# myir register map
Vendor: overlord; File version: 0.0.0
CPU: CA53 r0p0, little endian, no MPU, FPU, I-cache, D-cache, 0 interrupt priority bits
Registers are 32-bit, read-write, reset 0x0 unless marked. A register's access mark holds for its fields unless they carry their own. Offsets are from the block's base; lines under a group give offsets from that group; [hi:lo] are bit positions; {n}, {i} and the like mark numbered series; 'fields as' and 'values as' point back to an identical list; <NAME> marks a mode.

## Memory map
0xFF0F0000 QSPI size 0x828 — Quad SPI Controller
0xFF160000 SD0 size 0xFE — SDIO 0 Controller
0xFF170000 SD1 size 0xFE — SDIO 0 Controller

## Further device data
cpus:
  a53.0 endian=little
  a53.1 endian=little
  a53.2 endian=little
  a53.3 endian=little
  r5f.0 endian=little
  r5f.1 endian=little
  pmu endian=little

## QSPI — Quad SPI Controller
Base 0xFF0F0000
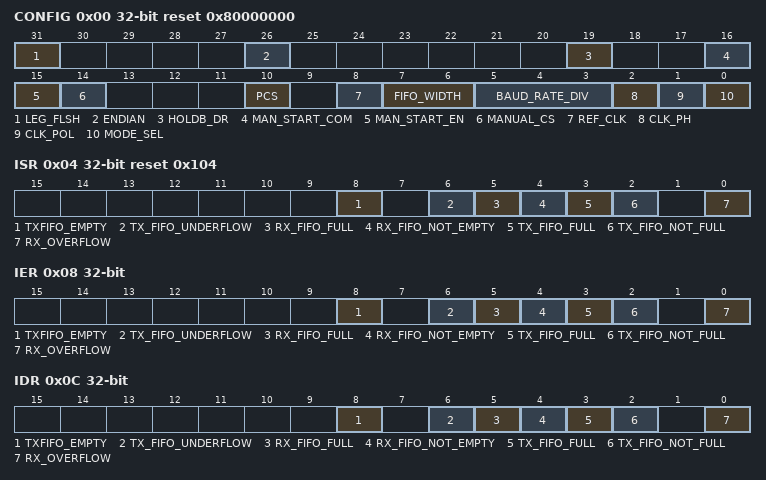
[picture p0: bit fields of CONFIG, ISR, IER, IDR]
0x00 CONFIG reset 0x80000000 — QSPI configuration register
  [31] LEG_FLSH — If this mode is disabled, the core will operate in standard SPI mode, with no dual- or quad-bit input or output capability; the extended bits will be configured as inputs to prevent any driver contention on these pins. If enabled, flash memory interface instructions are automatically recognized and the I/O configured accordingly.
  [26] ENDIAN — 1: big endian format when writing to the transmit data register 0x1C or reading from the receive data register 0x20.
  [19] HOLDB_DR — If not set, then external pull up is required on HOLDb and WPn pins. Note that this bit doesn't affect the quad (4-bit) mode as Controller always drives these pins in quad mode. It is highly recommended to set this bit always(irrespective of mode of operation) while using QSPI.
  [16] MAN_START_COM
  [15] MAN_START_EN
  [14] MANUAL_CS
  [10] PCS — In manual CS mode, this bit should be programmed before writing Transmit Data Registers (TXDx).
  [8] REF_CLK — Must be 0
  [7:6] FIFO_WIDTH — All other settings are not supported.
  [5:3] BAUD_RATE_DIV — This is the only baud rate setting that can be used if the loopback clock is enabled [USE_LPBK]. 001: divide by 4 010: divide by 8 011: divide by 16 100: divide by 32 101: divide by 64 110: divide by 128 111: divide by 256
  [2] CLK_PH
  [1] CLK_POL
  [0] MODE_SEL — In other boot modes, this bit must be set before using QSPI.
0x04 ISR reset 0x104 — Interrupt Status
  [8] TXFIFO_EMPTY — 1: TX FIFO is empty.
  [6] TX_FIFO_UNDERFLOW — 1: underflow is detected. Write 1 to this bit location to clear
  [5] RX_FIFO_FULL — 1: FIFO is full.
  [4] RX_FIFO_NOT_EMPTY — 1: FIFO has more than or equal to RX THRESHOLD entries.
  [3] TX_FIFO_FULL
  [2] TX_FIFO_NOT_FULL — 1: FIFO has less than TX THRESHOLD entries.
  [0] RX_OVERFLOW — 1: overflow occurred. Write 1 to this bit location to clear.
0x08 IER — Interrupt Enable
  [8] TXFIFO_EMPTY, [6] TX_FIFO_UNDERFLOW, [5] RX_FIFO_FULL, [4] RX_FIFO_NOT_EMPTY, [3] TX_FIFO_FULL, [2] TX_FIFO_NOT_FULL, [0] RX_OVERFLOW
0x0C IDR — Interrupt Disable
  fields as IER
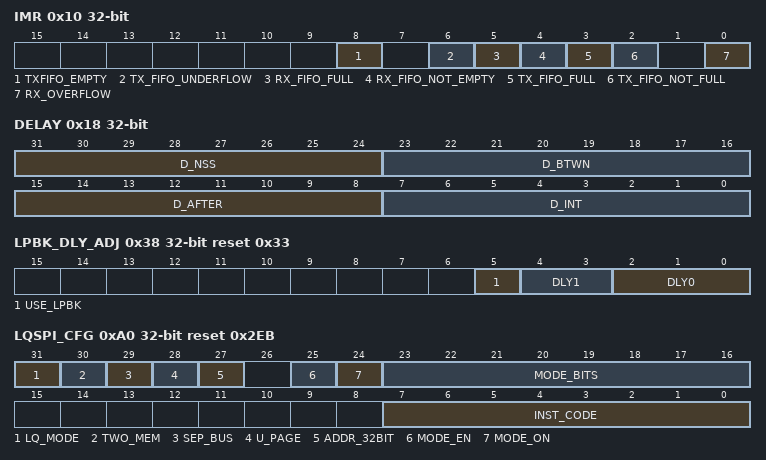
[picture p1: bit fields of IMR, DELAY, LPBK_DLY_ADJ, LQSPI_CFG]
0x10 IMR — Interrupt Un-Mask (enabled)
  fields as IER
0x14 LQSPI_EN — LQSPI Enable
  [0] SPI_EN — 1: enable the SPI. Note: Change this value only when controller is not communicating with the memory device.
0x18 DELAY — Timing Control Delay
  [31:24] D_NSS, [23:16] D_BTWN, [15:8] D_AFTER, [7:0] D_INT
0x1C TXD0 — Transmit Data, 4 Bytes
  [31:0] TXD
0x20 RX_DATA — Receive Data in RX FIFO
  [31:0] RX_FIFO_DATA
0x24 SLAVE_IDLE_COUNT reset 0xFF
0x28 TX_THRES reset 0x1 — TX FIFO Threshold
  [31:0] THRESHOLD_OF_TX_FIFO
0x2C RX_THRES reset 0x1 — RX FIFO Threshold
  [31:0] THRESHOLD_OF_RX_FIFO
0x30 GPIO reset 0x1 — Write Protection Output
  [0] WP_N — 0: output low. 1: output high (reset default). The active low function may be inverted externally for devices requiring an active high write protect signal. Note: Change this value only when controller is not communicating with the memory device.
0x38 LPBK_DLY_ADJ reset 0x33 — Loopback Master Clock Delay Adjustment
  [5] USE_LPBK — Note: Change this value only when controller is not communicating with the memory device.
  [4:3] DLY1 — Note: Change this value only when controller is not communicating with the memory device.
  [2:0] DLY0 — Note: Change this value only when controller is not communicating with the memory device.
0x80 TXD1 — Transmit Data, 1 Byte
  [31:0] TXD — In little endian mode (default), only bits 7:0 are valid, bits 31:8 are ignored. In big endian mode, only the 8 MSB bits are valid.
0x84 TXD2 — Transmit Data, 2 Byte
  [31:0] TXD — In little endian mode (default), only bits 15:0 are valid, bits 31:16 are ignored. In big endian mode, only the 16 MSB bits are valid.
0x88 TXD3 — Transmit Data, 3 Bytes
  [31:0] TXD — In little endian mode (default), only bits 23:0 are valid, bits 31:24 are ignored. In big endian mode, only the 24 MSB bits are valid.
0xA0 LQSPI_CFG reset 0x2EB — Configuration
  [31] LQ_MODE — 1: Legacy LQSPI, Linear Quad-SPI. Note: Change this value only when controller is not communicating with the memory device.
  [30] TWO_MEM — 1: Two memory devices. Note: Change this value only when controller is not communicating with the memory device.
  [29] SEP_BUS — 1: Separate memory intefaces. This bit only has meaning if [TWO_MEM] = 1. Note: Change this value only when controller is not communicating with the memory device.
  [28] U_PAGE — 1: Upper memory page. This bit only has meaning if: [TWO_MEM] = 1 (two devices) [SEP_BUS] = 0 (one interface) IO mode is not supported in LQSPI; [U_PAGE] selects the lower or upper memory for configuration or read/write operations. Note: Change this value only when controller is not communicating with the memory device.
  [27] ADDR_32BIT — 1: Five zero bits & lower 27 bits of AXI address. Note: Change this value only when controller is not communicating with the memory device.
  [25] MODE_EN — 1: Send MODE_BITS[23:16]. Must be set = 1 for dual or quad I/O read (specified through [7:0]). Must be clear = 0 for all other read modes as they do not have mode bits. If this bit is 0, [MODE_ON, 24] and [MODE_BITS] are ignored. Relationship of bits [25], [24] and [23:16] are related: if ( [ Bit25 == 0 ] && [ Bit24 == x ] ) then [ Bits23:16 = x ] if ( [ Bit25 == 1 ] && [ Bit24 == 0 ] ) then [ Bits23:16 = ~(8'bxx10xxxx) ] if ( [ Bit25 == 1 ] && [ Bit24 == 1 ] ) then [ Bits23:16 = 8'bxx10xxxx ]. Note: Change this value only when controller is not communicating with the memory device.
  [24] MODE_ON — 0: Instruction code is sent for all read transfers. 1: Instruction code is sent only for first read transfer. This bit applies when [MODE_EN, 25] is set = 1. This bit is configured in association with [MODE_BITS]. For Winbond devices, this bit must be set = 1 if the [MODE_BITS] = 8'bxx10xxxx, else clear = 0. Note: Change this value only when the controller is not communicating with the memory device.
  [23:16] MODE_BITS — These bits apply when [MODE_EN, 25] = 1. Required for both dual I/O read and quad I/O read. See Flash memory vendor's datasheet for more information on the mode bits. For the Winbond device, the continuous read mode value is 8'bxx10xxxx to skip the instruction code for the next read transfer, else instruction code is sent for all read transfers. Bit 24 has to be configured accordingly with this value. Note: Change this value only when controller is not communicating with the memory device.
  [7:0] INST_CODE — The known read instruction codes are: 8'h03 - Read 8'h0B - Fast read 8'h3B - Fast read dual output 8'h6B - Fast read quad output 8'hBB - Fast read dual I/O 8'hEB - Fast read quad I/O 8'h13 - Four Byte Address Read 8'h0C - Four Byte Address Fast read 8'h3C - Four Byte Address Fast read dual output 8'h6C - Four Byte Address Fast read quad output 8'hBC - Four Byte Address Fast read dual I/O 8'hEC - Four Byte Address Fast read quad I/O This is a static signal - should not be changed while controller is actively transmitting/receiving data to/from Flash device
0xA4 LQSPI_STS 9-bit — Status
  [2] D_FSM_ERR, [1] WR_RECVD
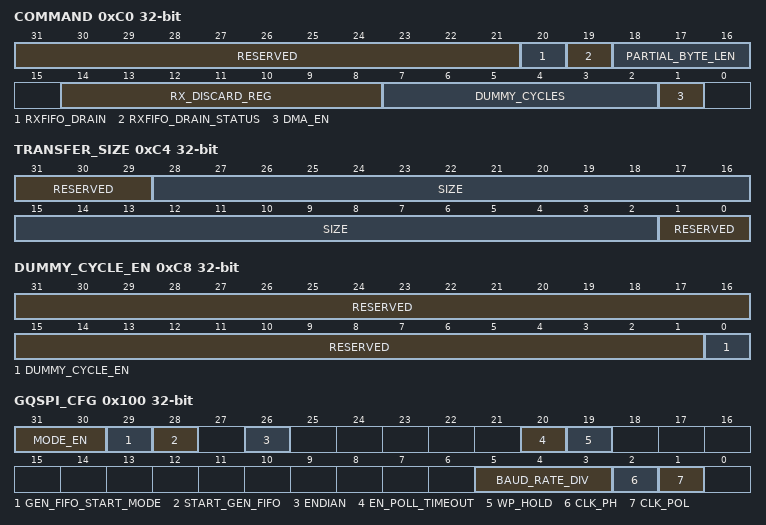
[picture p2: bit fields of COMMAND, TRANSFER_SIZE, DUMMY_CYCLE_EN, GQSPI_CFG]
0xC0 COMMAND — Command control
  [31:21] RESERVED — Return 0 when read. Writes ignored.
  [20] RXFIFO_DRAIN — This bit can be set for any write transfer to the Flash so that the HW will discard the data captured while transmitting the write data. 0: Do not discard the data in RXFIFO. 1: Discard the data in RXFIFO. Note: Change this value only when controller is not communicating with the memory device.
  [19] RXFIFO_DRAIN_STATUS — 0: RXFIFO_DRAIN is reset. 1: RXFIFO_DRAIN is set.
  [18:16] PARTIAL_BYTE_LEN — (TXDx length - PARTIAL_BYTE_LEN) is the number of bits to be transmitted For example, if only 4 bits to be transmitted, program PARTIAL_BYTE_LEN with a value of 4 and then configure TXD1 register. Similar way to transmit 12 bits, program PARTIAL_BYTE_LEN a value of 4 and then configure TXD2 register. Value in this files is cleared by HW soon after completing transmission of partial byte. SW need to write into this register again if need to transfer partial byte. This is a static signal - should not be changed while controller is actively transmitting/receiving data to/from Flash device
  [14:8] RX_DISCARD_REG — In general value in this field should be equal to QSPI clocks required to transmit Command+Address+Dummy cycles. This is a static signal - should not be changed while controller is actively transmitting/receiving data to/from Flash device
  [7:2] DUMMY_CYCLES — This is a static signal - should not be changed while controller is actively transmitting/receiving data to/from Flash device
  [1] DMA_EN — And the encoding is as mentioned below {DMA_EN, LQSPI_CFG[31]}: 01: Linear Mode. 10: DMA Mode. Others: reserved. Never set both the [DMA_EN] and LQSPI_SFG [31] bits to 1 as it is not a valid condition. This is a static signal - should not be changed while controller is actively transmitting/receiving data to/from Flash device
0xC4 TRANSFER_SIZE
  [31:29] RESERVED — Return 0 when read. Writes ignored.
  [28:2] SIZE — (2 lsb's are 0) The value in this register signifies the number of words to be read from memory. This is a static signal - should not be changed while controller is actively transmitting/receiving data to/from Flash device
  [1:0] RESERVED — Return 0 when read. Writes ignored.
0xC8 DUMMY_CYCLE_EN — Dummy Cycles Enable
  [31:1] RESERVED — Return 0 when read. Writes ignored.
  [0] DUMMY_CYCLE_EN — This bit is applicable only in Linear mode. This bit should not be used in DMA mode. 0: Disable using dummy cycle value. 1: Enable using dummy cycle value. This is a static signal - should not be changed while controller is actively transmitting/receiving data to/from Flash device
0xFC MOD_ID reset 0x1090101 — Module Identification
0x100 GQSPI_CFG — GQSPI Configuration
  [31:30] MODE_EN
  [29] GEN_FIFO_START_MODE — 1: Manual Start Mode. Note: Change this value only when controller is not communicating with the memory device.
  [28] START_GEN_FIFO — 0:disable executing requests. 1: enable executing requests. Note: Change this value only when controller is not communicating with the memory device.
  [26] ENDIAN — 1: big endian. Note: Change this value only when controller is not communicating with the memory device.
  [20] EN_POLL_TIMEOUT — 1: enable. Note: Change this value only when controller is not communicating with the memory device.
  [19] WP_HOLD — If not set, then external pull up is required on HOLDb and WPn pins. Note that this bit doesn't affect the quad(4-bit) mode as Controller always drives these pins in quad mode. It is highly recommended to set this bit always(irrespective of mode of operation) while using GQSPI Note: Change this value only when controller is not communicating with the memory device.
  [5:3] BAUD_RATE_DIV — 001: divide by 4. 010: divide by 8. 011: divide by 16. 100: divide by 32. 101: divide by 64. 110: divide by 128. 111: divide by 256. Note: 000 is requried for loopback, [USE_LPBK]. Note: Change this value only when controller is not communicating with the memory device.
  [2] CLK_PH — Note: Change this value only when controller is not communicating with the memory device.
  [1] CLK_POL — 0: QSPI clock is quiescent low. 1: QSPI clock is quiescent high. Note: For [CLK_PH, CLK_POL], only 2'b11 and 2'b00 are supported. Note: Change this value only when controller is not communicating with the memory device.
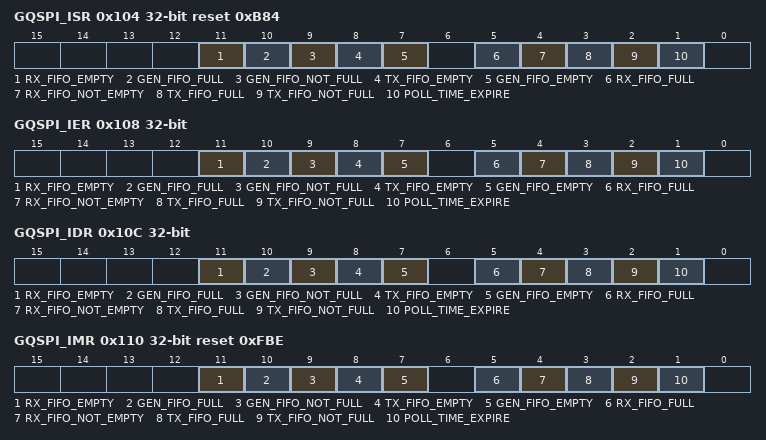
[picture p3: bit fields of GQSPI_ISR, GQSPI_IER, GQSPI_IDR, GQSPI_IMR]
0x104 GQSPI_ISR reset 0xB84 — Generic QSPI interrupt status
  [11] RX_FIFO_EMPTY, [10] GEN_FIFO_FULL, [9] GEN_FIFO_NOT_FULL, [8] TX_FIFO_EMPTY, [7] GEN_FIFO_EMPTY, [5] RX_FIFO_FULL, [4] RX_FIFO_NOT_EMPTY, [3] TX_FIFO_FULL, [2] TX_FIFO_NOT_FULL, [1] POLL_TIME_EXPIRE
0x108 GQSPI_IER — GQSPI Interrupt Enable
  fields as GQSPI_ISR
0x10C GQSPI_IDR — GQSPI Interrupt disable
  fields as GQSPI_ISR
0x110 GQSPI_IMR reset 0xFBE — GQSPI Interrupt Mask
  fields as GQSPI_ISR
0x114 GQSPI_EN — GQSPI_Enable
  [0] GQSPI_EN
0x11C GQSPI_TXD — GQSPI Transmit Data
  [31:0] TX_DATA
0x120 GQSPI_RXD — GQSPI Receive Data
  [31:0] RX_DATA
0x128 GQSPI_TX_THRESH reset 0x1 — GQSPI TX FIFO Threshold Level
  [5:0] LEVEL_TX_FIFO — Note: Change this value only when controller is not communicating with the memory device.
0x12C GQSPI_RX_THRESH reset 0x1 — GQSPI RX FIFO Threshold Level
  [5:0] LEVEL_RX_FIFO
0x130 GQSPI_GPIO reset 0x1 — GQSPI GPIO for Write Protect
  [0] WP_N — Write Protect output for flash devices supporting this function. Active low (may be inverted externally to the core if required for flash devices requiring active high write protect signal.) Note: Change this value only when controller is not communicating with the memory device.
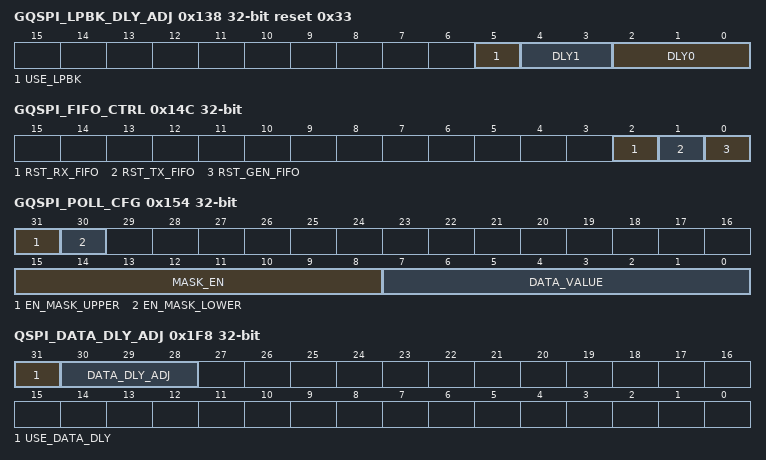
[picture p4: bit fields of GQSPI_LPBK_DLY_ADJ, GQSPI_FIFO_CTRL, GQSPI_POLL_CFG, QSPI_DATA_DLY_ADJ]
0x138 GQSPI_LPBK_DLY_ADJ reset 0x33 — GQSPI Loopback clock delay adjustment Register
  fields as LPBK_DLY_ADJ
0x140 GQSPI_GEN_FIFO — GQSPI Generic FIFO Configuration
  [19:0] GEN_DATA
0x144 GQSPI_SEL — GQSPI Select
  [0] GENERIC_QSPI_SEL — Note: Change this value only when controller is not communicating with the memory device.
0x14C GQSPI_FIFO_CTRL — GQSPI FIFO Control
  [2] RST_RX_FIFO — This bit should be used only when GQSPI is in IO mode (GQSPI_CFG.MODE_EN=0x0). Switch to IO mode if operating in DMA Mode. After RST_RX_FIFO bit is written, Controller takes few clock cycles to update the RX_FIFO_Empty status bit. Software can read the RX_FIFO_empty bit twice to allow enough time for the controller to update the status bit.
  [1] RST_TX_FIFO — After RST_TX_FIFO bit is written, Controller takes few clock cycles to update the TX_FIFO_Empty status bit. Software can read the TX_FIFO_empty bit twice to allow enough time for the controller to update the status bit.
  [0] RST_GEN_FIFO — After RST_GEN_FIFO bit is written, Controller takes few clock cycles to update the Gen_FIFO_Empty status bit. Software can read the Gen_FIFO_empty bit twice to allow enough time for the controller to update the status bit.
0x150 GQSPI_GF_THRESH reset 0x10 — GQSPI Generic FIFO Threshold Level
  [4:0] LEVEL_GF_FIFO — Note: Change this value only when controller is not communicating with the memory device.
0x154 GQSPI_POLL_CFG — GQSPI Poll Configuration Register
  [31] EN_MASK_UPPER — 1: Enable. Note: Change this value only when controller is not polling.
  [30] EN_MASK_LOWER — 1: Enable. This is a static signal - should not be changed while polling operation is in progress.
  [15:8] MASK_EN — When all the bits are zero, no masking is used and all the 8 bits of POLL_DATA field will be used for comparison during Poll. Note: Change this value only when controller is not polling.
  [7:0] DATA_VALUE — When Poll bit of Generic FIFO is set, Generic QSPI Controller continuously reads the data and checks with the POLL_DATA value. When the received data matches with the POLL_DATA filed, Generic QSPI Controller continues executing the next entry in the Generic FIFO. If the value is not matched and EN_POLL_TIMEOUT is set, poll operation will be terminated after POLL_TIMEOUT clock cycles. This is a static signal - should not be changed while polling operation is in progress.
0x158 GQSPI_P_TIMEOUT — GQSPI Poll Time out
  [31:0] VALUE — Interrupt will be provided to indicate that the timer is expired. Note: Change this value only when controller is not polling.
0x1F8 QSPI_DATA_DLY_ADJ — QSPI RX Data Delay
  [31] USE_DATA_DLY, [30:28] DATA_DLY_ADJ
0x1FC GQSPI_MOD_ID reset 0x10A0000 — GQSPI Module Identification register
  [31:0] MOD_ID
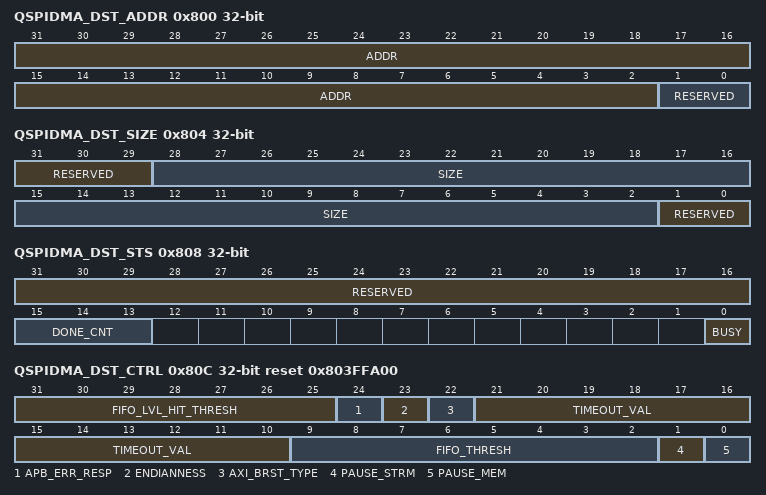
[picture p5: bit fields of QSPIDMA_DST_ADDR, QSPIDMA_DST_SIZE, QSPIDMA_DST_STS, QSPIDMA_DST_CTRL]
0x800 QSPIDMA_DST_ADDR — DMA destination memory address
  [31:2] ADDR — (2 lsb's are 0) This field must be written initially before a DMA operation is started. In this case, it indicates the memory destination address the DMA will begin writing to. Note: Change this value only when controller is not communicating with the memory device.
  [1:0] RESERVED — Return 0 when read. Writes ignored.
0x804 QSPIDMA_DST_SIZE — DMA transfer payload
  [31:29] RESERVED — Return 0 when read. Writes ignored.
  [28:2] SIZE — (2 lsb's are 0) The action of writing to this register starts a DMA transfer of length SIZE, moving data from the stream interface to ADDR. In this case, it indicates the total payload that the DMA will move from stream to memory. Note: Change this value only when controller is not communicating with the memory device.
  [1:0] RESERVED — Return 0 when read. Writes ignored.
0x808 QSPIDMA_DST_STS — General DST DMA Status
  [31:16] RESERVED — Return 0 when read. Writes ignored.
  [15:13] DONE_CNT — A finished transfer is acknowledged by clearing the interrupt status flag 'DONE". This count is cleared by an explicit write of 3'b111 to this field.
  [0] BUSY — BUSY=0: implies DMA is DONE with the transfer, the DST FIFO and any associated pipeline registers are empty. DMA may accept a new command. Note that, BUSY essentially indicates that the DMA still has remaining work to do. BUSY will reflect this status irrespective of whether the PAUSE_* is asserted or not.
0x80C QSPIDMA_DST_CTRL reset 0x803FFA00 — General DST DMA Control
  [31:25] FIFO_LVL_HIT_THRESH — 7'h00: Reserved etc 7'h0F: Reserved 7'h10: Threshold is 17 entries etc 7'h7A: Threshold is 123 entries 7'h7B: Reserved etc 7'h7F: Reserved Note that "7'h10" is the minimum and "7'h7A" is the max value that should be programmed This is a static signal - should not be changed while block is actively processing commands
  [24] APB_ERR_RESP
  [23] ENDIANNESS
  [22] AXI_BRST_TYPE
  [21:10] TIMEOUT_VAL — There are 2 physical timers, qualified with TIMEOUT_EN, that will compare against this value: 1. Timeout counter starts to run when data is provided to the AXI write channel (memory) interface and backpressure is observed. As soon as backpressure is removed, the timer is reset. When timer expires, it stops running. 2. Timeout counter runs whenever the DMA is active. Whenever a data beat is provided by the SSS, the timer is reset. When timer expires, it stops running. TIMEOUT_VAL field is interpreted as follows: Final timeout value = TIMEOUT_VAL * timeout_prescale_period where "timeout_prescale_period" is the period of the enable that is generated by the TIMEOUT_PRE. Examples (prescaler set to maximum of 4096 clk (~2.5ns) cycles) 12'h000: Final Timeout after 1 * (4096 * 2.5ns)] => 10.244 us 12'h001: Final Timeout after 2 * (4096 * 2.5ns)] => 20.48 us etc 12'hFFF: Final Timeout after 4096 * (4096 * 2.5ns)] => 41.94 ms Note that if PAUSE_MEM is asserted, timeout counter #1 will be paused and if PAUSE_STRM is asserted, timeout counter #2 will be paused. When either of the 2 timers expire, this register requires an explicit write of 12'hFFF to clear them - both will be cleared. Note: Change this value only when controller is not processing commands.
  [9:2] FIFO_THRESH — This is the FIFO threshold used to trigger the FIFO_THRESHOLD_HIT interrupt. 8'h00: Threshold is 0 entries 8'h01: Threshold is 1 entry etc 8'h80: Threshold is 128 entries Note that the interrupt will be triggered when the FIFO hits this threshold, irrespective of whether it is on the way up or down. Note: Change this value only when controller is not processing commands.
  [1] PAUSE_STRM — This in effect will lead to the emptying of the DST FIFO. 0: DMA operates as usual. If previously PAUSED, it will continue on where it left off. Note. H/W has no means to apply backpressure to the stream interface. If PAUSE_STRM is asserted, the DMA will drop the stream data. This makes PAUSE mode functionally equivalent to as if the fifo were full. The value of PAUSE_STRM may therefore be limited to debug/verification only.
  [0] PAUSE_MEM — This in effect will eventually lead to the filling of the DST FIFO. Write memory commands that are already outstanding will continue to be processed, but no new write commands will be issued to memory while PAUSE_MEM is asserted. 0: DMA operates as usual. If previously PAUSED, it will continue on where it left off.
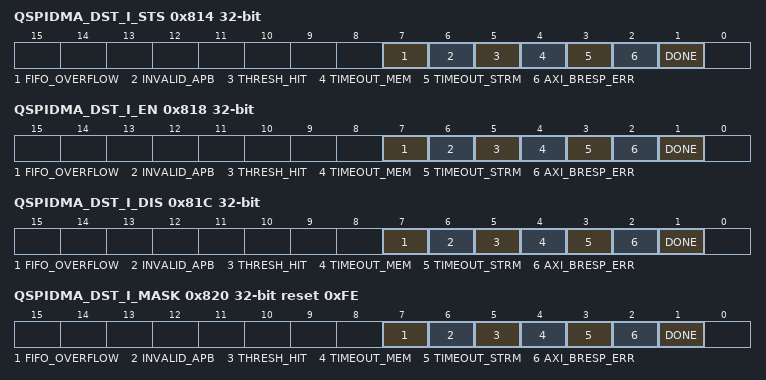
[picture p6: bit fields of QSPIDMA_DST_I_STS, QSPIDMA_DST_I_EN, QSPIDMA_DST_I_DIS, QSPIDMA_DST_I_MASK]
0x814 QSPIDMA_DST_I_STS — DST DMA Interrupt Status
  [7] FIFO_OVERFLOW — No backpressure mechanism exists on the stream interface in this direction. If the FIFO is full and 1 more data beat is produced by the stream interface, this bit will be set and the data beat will be discarded. If [PAUSE_STRM] is asserted and the stream interface produces a beat of data, the beat will be discarded and [FIFO_OVERFLOW] will be set.
  [6] INVALID_APB — The access request did not reach a register.
  [5] THRESH_HIT — The watermark value is set via the [FIFO_THRESH] bitfield.
  [4] TIMEOUT_MEM — DST DMA sees backpressure on AXI write data interface. Refer to [TIMEOUT_VAL] description for exact timeout duration and conditions.
  [3] TIMEOUT_STRM — DST DMA sees delay on SSS DST interface. Refer to [TIMEOUT_VAL] description for exact timeout duration and conditions.
  [2] AXI_BRESP_ERR — BRESP=DECERR/SLVERR.
  [1] DONE — The last associated AXI memory write command has been issued and processed (SIZE=0), all data has been sent (DST FIFO is empty) and all outstanding BRESP's have been received.
0x818 QSPIDMA_DST_I_EN — DST DMA Interrupt Enable
  [7] FIFO_OVERFLOW, [6] INVALID_APB, [5] THRESH_HIT, [4] TIMEOUT_MEM, [3] TIMEOUT_STRM, [2] AXI_BRESP_ERR, [1] DONE
0x81C QSPIDMA_DST_I_DIS — DST DMA Interrupt Disable
  fields as QSPIDMA_DST_I_EN
0x820 QSPIDMA_DST_I_MASK reset 0xFE — DST DMA Interrupt Mask
  fields as QSPIDMA_DST_I_EN
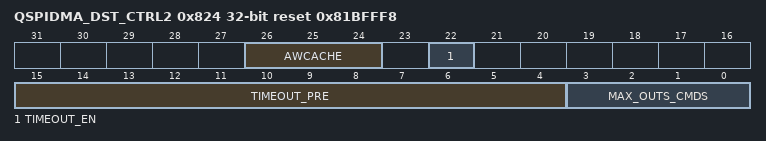
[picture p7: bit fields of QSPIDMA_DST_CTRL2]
0x824 QSPIDMA_DST_CTRL2 reset 0x81BFFF8 — General DST DMA Control Reg 2
  [26:24] AWCACHE — Bit[25]: AXI AwCache[2] signal. Bit[26]: AXI AwCache[3] signal. Note: AXI AwCache[1] signal is always driven to 1. Note: Change this value only when controller is not processing commands.
  [22] TIMEOUT_EN — 1: enable. Note: Change this value only when controller is not processing commands.
  [15:4] TIMEOUT_PRE — 5ns) cycles (Refer to [TIMEOUT_VAL] description). The [TIMEOUT_PRE] field is interpreted as follows: 000: Prescaler enables timer every cycle. 001: Prescaler enables timer every 2 cycles. .. FFF: Prescaler enables timer every 4096 cycles. Note: Change this value only when controller is not processing commands.
  [3:0] MAX_OUTS_CMDS — The field is interpreted as follows: 0: Max of 1 Outstanding Write command allowed 1 to 8: Max of 2 to 9 Outstanding Write commands allowed Note: Change this value only when controller is not processing commands.
0x828 QSPIDMA_DST_ADDR_MSB — DMA destination memory address (MSBs)
  [11:0] ADDR_MSB — Refer to the description for [QSPIDMA_DST_ADDR]. This field is the 12 msbs of the full 44-bit DST address. MSBs for 44-bit DMA Destination Address. The address is comprised of three fields: [ADDR_MSB] with 12 MSBs. QSPIDMA_DST_ADDR [ADDR] with 30 bits. 00 of two LSBs. Note: Change this value only when controller is not processing commands.

## Licence text in the file
// SPDX-License-Identifier: MIT
